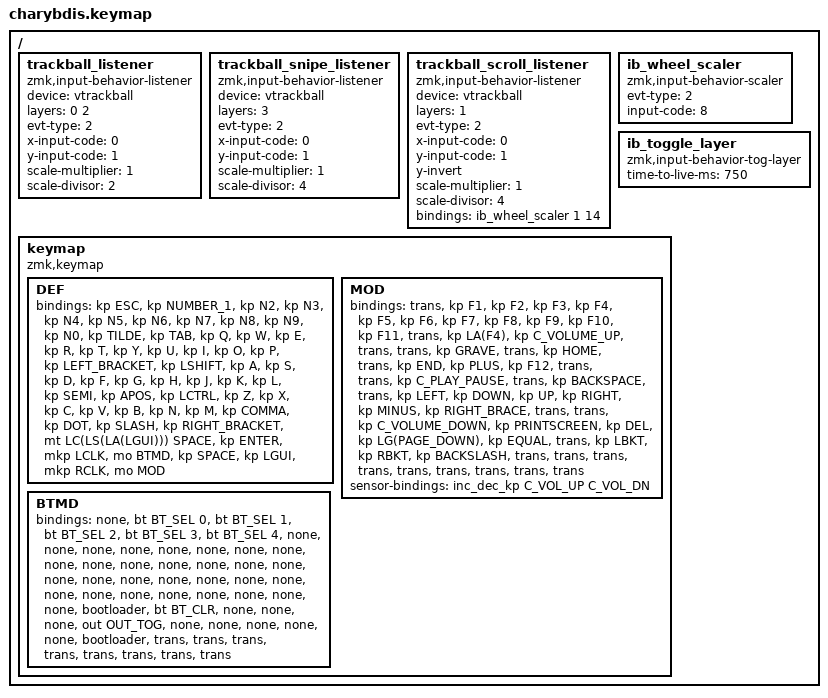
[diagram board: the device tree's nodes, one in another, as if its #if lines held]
#include <behaviors.dtsi>
#include <dt-bindings/zmk/keys.h>
#include <dt-bindings/zmk/mouse.h>
#include <dt-bindings/zmk/bt.h>
#include <dt-bindings/zmk/ext_power.h>
#include <dt-bindings/zmk/outputs.h>

/ {
#ifdef DT_NODELABEL_vtrackball
    trackball_listener {
        compatible = "zmk,input-behavior-listener";
        device = <&vtrackball>;
        layers = <0 2>;
        evt-type = <2>;       /* INPUT_EV_REL */
        x-input-code = <0>;   /* INPUT_REL_X */
        y-input-code = <1>;   /* INPUT_REL_Y */
        scale-multiplier = <1>;
        scale-divisor = <2>;
    };

    trackball_snipe_listener {
        compatible = "zmk,input-behavior-listener";
        device = <&vtrackball>;
        layers = <3>;
        evt-type = <2>;       /* INPUT_EV_REL */
        x-input-code = <0>;   /* INPUT_REL_X */
        y-input-code = <1>;   /* INPUT_REL_Y */
        scale-multiplier = <1>;
        scale-divisor = <4>;
    };

    trackball_scroll_listener {
        compatible = "zmk,input-behavior-listener";
        device = <&vtrackball>;
        layers = <1>;
        evt-type = <2>;       /* INPUT_EV_REL */
        x-input-code = <0>;   /* INPUT_REL_X */
        y-input-code = <1>;   /* INPUT_REL_Y */
        y-invert;
        scale-multiplier = <1>;
        scale-divisor = <4>;
        bindings = <&ib_wheel_scaler 1 14>;
    };

    ib_wheel_scaler: ib_wheel_scaler {
        compatible = "zmk,input-behavior-scaler";
        #binding-cells = <2>;
        evt-type = <2>;       /* INPUT_EV_REL */
        input-code = <8>;     /* INPUT_REL_WHEEL */
    };

    ib_toggle_layer: ib_toggle_layer {
        compatible = "zmk,input-behavior-tog-layer";
        #binding-cells = <1>;
        time-to-live-ms = <750>;
    };
#endif

#define DEF 0
#define MOD 1
#define BTMD 2

    keymap {
        compatible = "zmk,keymap";

        DEF {
            bindings = <
                &kp ESC &kp NUMBER_1 &kp N2 &kp N3 &kp N4 &kp N5 &kp N6 &kp N7 &kp N8 &kp N9 &kp N0 &kp TILDE
                &kp TAB &kp Q &kp W &kp E &kp R &kp T &kp Y &kp U &kp I &kp O &kp P &kp LEFT_BRACKET
                &kp LSHIFT &kp A &kp S &kp D &kp F &kp G &kp H &kp J &kp K &kp L &kp SEMI &kp APOS
                &kp LCTRL &kp Z &kp X &kp C &kp V &kp B &kp N &kp M &kp COMMA &kp DOT &kp SLASH &kp RIGHT_BRACKET
                    &mt LC(LS(LA(LGUI))) SPACE &kp ENTER &mkp LCLK &mo BTMD &kp SPACE
                    &kp LGUI &mkp RCLK &mo MOD
            >;
        };

        MOD {
            bindings = <
                &trans &kp F1 &kp F2 &kp F3 &kp F4 &kp F5 &kp F6 &kp F7 &kp F8 &kp F9 &kp F10 &kp F11
                &trans &kp LA(F4) &kp C_VOLUME_UP &trans &trans &kp GRAVE &trans &kp HOME &trans &kp END &kp PLUS &kp F12
                &trans &trans &kp C_PLAY_PAUSE &trans &kp BACKSPACE &trans &kp LEFT &kp DOWN &kp UP &kp RIGHT &kp MINUS &kp RIGHT_BRACE
                &trans &trans &kp C_VOLUME_DOWN &kp PRINTSCREEN &kp DEL &kp LG(PAGE_DOWN) &kp EQUAL &trans &kp LBKT &kp RBKT &kp BACKSLASH &trans
                    &trans &trans &trans &trans &trans
                    &trans &trans &trans
            >;

#ifdef DT_NODELABEL_vtrackball
            sensor-bindings = <&inc_dec_kp C_VOL_UP C_VOL_DN>;
#endif
        };

        BTMD {
            bindings = <
                &none &bt BT_SEL 0 &bt BT_SEL 1 &bt BT_SEL 2 &bt BT_SEL 3 &bt BT_SEL 4 &none &none &none &none &none &none
                &none &none &none &none &none &none &none &none &none &none &none &none
                &none &none &none &none &none &none &none &none &none &none &none &none
                &bootloader &bt BT_CLR &none &none &none &out OUT_TOG &none &none &none &none &none &bootloader
                    &trans &trans &trans &trans &trans
                    &trans &trans &trans
            >;
        };
    };
};
